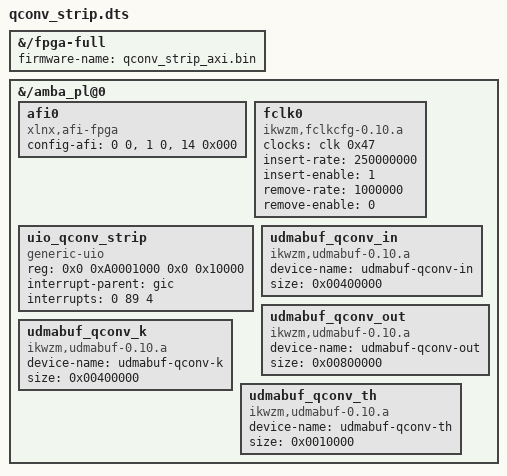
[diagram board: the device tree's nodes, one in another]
/dts-v1/; /plugin/;
/ {
	fragment@0 {
		target-path = "/fpga-full";
		__overlay__ {
			firmware-name = "qconv_strip_axi.bin";
		};
        };
	fragment@1 {
		target-path = "/amba_pl@0";
		__overlay__ {
			afi0 {
				compatible    = "xlnx,afi-fpga";
				config-afi    = <0 0>, <1 0>, <14 0x000>;
			};
			fclk0 {
				compatible    = "ikwzm,fclkcfg-0.10.a";
				clocks        = <&clk 0x47>;
				insert-rate   = "250000000";
				insert-enable = <1>;
				remove-rate   = "1000000";
				remove-enable = <0>;
			};
		};
	};
	fragment@2 {
		target-path = "/amba_pl@0";
		#address-cells = <2>;
		#size-cells = <2>;

		__overlay__ {
			#address-cells = <2>;
			#size-cells = <2>;

			uio_qconv_strip {
				compatible = "generic-uio";
				reg = <0x0 0xA0001000 0x0 0x10000>;
				interrupt-parent = <&gic>;
				interrupts = <0 89 4>;
	                };

			udmabuf_qconv_in {
				compatible  = "ikwzm,udmabuf-0.10.a";
				device-name = "udmabuf-qconv-in";
				size = <0x00400000>;
	                };

			udmabuf_qconv_out {
				compatible = "ikwzm,udmabuf-0.10.a";
				device-name = "udmabuf-qconv-out";
				size = <0x00800000>;
			};
			
			udmabuf_qconv_k {
				compatible = "ikwzm,udmabuf-0.10.a";
				device-name = "udmabuf-qconv-k";
				size = <0x00400000>;
			};

			udmabuf_qconv_th {
				compatible = "ikwzm,udmabuf-0.10.a";
				device-name = "udmabuf-qconv-th";
				size = <0x0010000>;
			};
                };
	} ;
} ;
